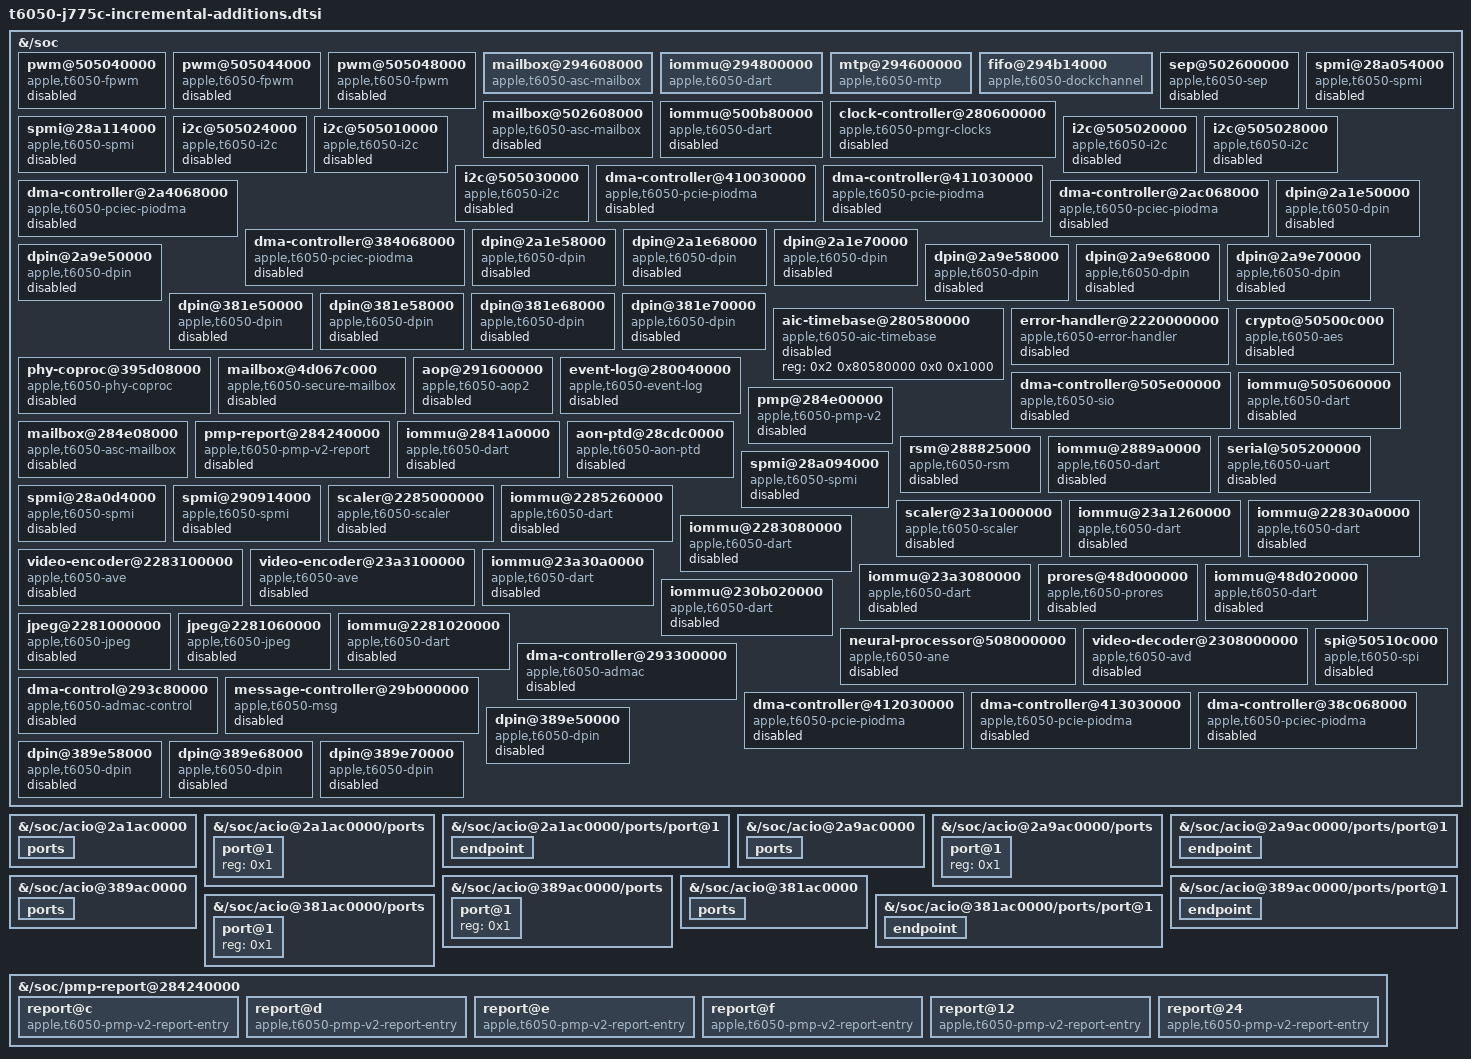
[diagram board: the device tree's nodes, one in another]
// SPDX-License-Identifier: GPL-2.0+ OR MIT
/* Property migration from Satya Benson's 86b1f365 J775c stack.
 * Retained board sources remain the baseline; this group is independently booted.
 * Copyright The Asahi Linux Contributors
 */
&{/soc} {
	pwm@505040000 {
		compatible = "apple,t6050-fpwm", "apple,s5l-fpwm";
		reg = <0x5 0x5040000 0x0 0x4000>;
		clocks = <&{/clock-ref}>;
		power-domains = <&{/soc/power-management@280900000/power-controller@2a8}>;
		#pwm-cells = <0x2>;
		status = "disabled";
	};
};

&{/soc} {
	pwm@505044000 {
		compatible = "apple,t6050-fpwm", "apple,s5l-fpwm";
		reg = <0x5 0x5044000 0x0 0x4000>;
		clocks = <&{/clock-ref}>;
		power-domains = <&{/soc/power-management@280900000/power-controller@2b0}>;
		#pwm-cells = <0x2>;
		status = "disabled";
	};
};

&{/soc} {
	pwm@505048000 {
		compatible = "apple,t6050-fpwm", "apple,s5l-fpwm";
		reg = <0x5 0x5048000 0x0 0x4000>;
		clocks = <&{/clock-ref}>;
		power-domains = <&{/soc/power-management@280900000/power-controller@2b8}>;
		#pwm-cells = <0x2>;
		status = "disabled";
	};
};

&{/soc/acio@2a1ac0000} {
	ports {
		#address-cells = <0x1>;
		#size-cells = <0x0>;
	};
};

&{/soc/acio@2a1ac0000/ports} {
	port@1 {
		reg = <0x1>;
	};
};

&{/soc/acio@2a1ac0000/ports/port@1} {
	endpoint {
		remote-endpoint = <&{/soc/spmi@28a188000/usb-pd@c/connector/ports/port@3/endpoint}>;
	};
};

&{/soc/acio@2a9ac0000} {
	ports {
		#address-cells = <0x1>;
		#size-cells = <0x0>;
	};
};

&{/soc/acio@2a9ac0000/ports} {
	port@1 {
		reg = <0x1>;
	};
};

&{/soc/acio@2a9ac0000/ports/port@1} {
	endpoint {
		remote-endpoint = <&{/soc/spmi@28a188000/usb-pd@a/connector/ports/port@3/endpoint}>;
	};
};

&{/soc/acio@389ac0000} {
	ports {
		#address-cells = <0x1>;
		#size-cells = <0x0>;
	};
};

&{/soc/acio@389ac0000/ports} {
	port@1 {
		reg = <0x1>;
	};
};

&{/soc/acio@389ac0000/ports/port@1} {
	endpoint {
		remote-endpoint = <&{/soc/spmi@28a188000/usb-pd@6/connector/ports/port@3/endpoint}>;
	};
};

&{/soc} {
	mailbox@294608000 {
		compatible = "apple,t6050-asc-mailbox", "apple,asc-mailbox-v4";
		reg = <0x2 0x94608000 0x0 0x4000>;
		interrupts = <0x0 0x0 0x2a4 0x4 0x0 0x0 0x2a5 0x4 0x0 0x0 0x2a6 0x4 0x0 0x0 0x2a7 0x4>;
		interrupt-names = "send-empty", "send-not-empty", "recv-empty", "recv-not-empty";
		#mbox-cells = <0x0>;
	};
};

&{/soc} {
	iommu@294800000 {
		compatible = "apple,t6050-dart", "apple,t8110-dart";
		reg = <0x2 0x94800000 0x0 0xc000>;
		interrupts = <0x0 0x0 0x293 0x4>;
		#iommu-cells = <0x1>;
		apple,dma-range = <0x100 0x4000 0x0 0xffff0000>;
	};
};

&{/soc} {
	mtp@294600000 {
		compatible = "apple,t6050-mtp", "apple,t6050-rtk-helper-asc4", "apple,mtp", "apple,rtk-helper-asc4";
		reg = <0x2 0x94600000 0x0 0x4000 0x2 0x94c00000 0x0 0xc4000>;
		reg-names = "asc", "sram";
		mboxes = <&{/soc/mailbox@294608000}>;
		iommus = <&{/soc/iommu@294800000} 0x0>;
		#helper-cells = <0x0>;
	};
};

&{/soc} {
	fifo@294b14000 {
		compatible = "apple,t6050-dockchannel", "apple,dockchannel";
		reg = <0x2 0x94b14000 0x0 0x1000>;
		reg-names = "irq";
		interrupts = <0x0 0x0 0x294 0x4>;
		ranges = <0x0 0x2 0x94b28000 0x10000>;
		nonposted-mmio;
		#address-cells = <0x1>;
		#size-cells = <0x1>;
		interrupt-controller;
		#interrupt-cells = <0x2>;
	};
};

&{/soc/acio@381ac0000} {
	ports {
		#address-cells = <0x1>;
		#size-cells = <0x0>;
	};
};

&{/soc/acio@381ac0000/ports} {
	port@1 {
		reg = <0x1>;
	};
};

&{/soc/acio@381ac0000/ports/port@1} {
	endpoint {
		remote-endpoint = <&{/soc/spmi@28a188000/usb-pd@8/connector/ports/port@3/endpoint}>;
	};
};

&{/soc} {
	sep@502600000 {
		compatible = "apple,t6050-sep", "apple,sep";
		reg = <0x5 0x2600000 0x0 0x88000 0x5 0x2050000 0x0 0x4000>;
		mboxes = <&{/soc/mailbox@502608000}>;
		mbox-names = "mbox";
		iommus = <&{/soc/iommu@500b80000} 0x0>;
		power-domains = <&{/soc/power-management@280900000/power-controller@298}>;
		clocks = <&{/soc/clock-controller@280600000} 0x1bf>;
		status = "disabled";
	};
};

&{/soc} {
	mailbox@502608000 {
		compatible = "apple,t6050-asc-mailbox", "apple,asc-mailbox-v4";
		reg = <0x5 0x2608000 0x0 0x4000>;
		interrupts = <0x0 0x0 0x215 0x4 0x0 0x0 0x216 0x4 0x0 0x0 0x217 0x4 0x0 0x0 0x218 0x4>;
		interrupt-names = "send-empty", "send-not-empty", "recv-empty", "recv-not-empty";
		#mbox-cells = <0x0>;
		status = "disabled";
	};
};

&{/soc} {
	iommu@500b80000 {
		compatible = "apple,t6050-dart", "apple,t8110-dart";
		reg = <0x5 0xb80000 0x0 0x20000>;
		interrupts = <0x0 0x0 0x21f 0x4>;
		#iommu-cells = <0x1>;
		apple,dma-range = <0x100 0x4000 0x0 0xffff0000>;
		apple,dma-offset = <0x0 0x0>;
		status = "disabled";
	};
};

&{/soc} {
	clock-controller@280600000 {
		compatible = "apple,t6050-pmgr-clocks", "apple,pmgr-clocks";
		reg = <0x2 0x80600000 0x0 0x1fc000 0x2 0x80900000 0x0 0x58000 0x2 0x80000000 0x0 0x80000 0x2 0x80210000 0x0 0x8000 0x2 0x80200000 0x0 0x4000 0x2 0x806f0000 0x0 0x4000 0x2 0x84000000 0x0 0x8000 0x2 0x84240000 0x0 0x40000 0x2 0x86000000 0x0 0x1000000 0x2 0x88300000 0x0 0x84000 0x2 0x88200000 0x0 0x80000 0x2 0x88f00000 0x0 0x18000 0x2 0x88000000 0x0 0x24000 0x2 0x88e00000 0x0 0xa8000 0x2 0x88360000 0x0 0x4000 0x5 0x9878000 0x0 0x4000 0x2 0x10e20000 0x0 0x12e8 0x2 0x10e40000 0x0 0xc020 0x2 0x10e50000 0x0 0x9048 0x2 0x10e70000 0x0 0xffe8 0x2 0x10050000 0x0 0x9018 0x2 0x10150000 0x0 0x9018 0x2 0x10250000 0x0 0x9018 0x2 0x10350000 0x0 0x9018 0x2 0x10450000 0x0 0x9018 0x2 0x10550000 0x0 0x9018 0x2 0x11e20000 0x0 0x12e8 0x2 0x11e40000 0x0 0xc020 0x2 0x11e50000 0x0 0x9048 0x2 0x11e70000 0x0 0xffe8 0x2 0x11050000 0x0 0x9018 0x2 0x11150000 0x0 0x9018 0x2 0x11250000 0x0 0x9018 0x2 0x11350000 0x0 0x9018 0x2 0x11450000 0x0 0x9018 0x2 0x11550000 0x0 0x9018 0x2 0x12e20000 0x0 0x12e8 0x2 0x12e40000 0x0 0xc020 0x2 0x12e50000 0x0 0x9048 0x2 0x12e70000 0x0 0xffe8 0x2 0x12050000 0x0 0x9018 0x2 0x12150000 0x0 0x9018 0x2 0x12250000 0x0 0x9018 0x2 0x12350000 0x0 0x9018 0x2 0x12450000 0x0 0x9018 0x2 0x12550000 0x0 0x9018 0x23 0x80600000 0x0 0x1e8000 0x23 0x80000000 0x0 0x80000 0x23 0x84000000 0x0 0x8000 0x23 0x88300000 0x0 0x84000 0x23 0x88200000 0x0 0x80000 0x23 0xe80000 0x0 0x30000 0x23 0xec0000 0x0 0x8000 0x23 0xed0000 0x0 0x8000 0x23 0xee0000 0x0 0x8000 0x23 0xef0000 0x0 0x8000 0x23 0xf00000 0x0 0x8000 0x23 0xe30000 0x0 0x8000 0x23 0xe70000 0x0 0x8000 0x23 0x88000000 0x0 0x8000>;
		#clock-cells = <0x1>;
		apple,pmgr = <&{/soc/power-management@280600000}>;
		status = "disabled";
	};
};

&{/soc} {
	spmi@28a054000 {
		compatible = "apple,t6050-spmi", "apple,t8142-spmi";
		reg = <0x2 0x8a054000 0x0 0x4000 0x2 0x8a044000 0x0 0x4000 0x2 0x8a040000 0x0 0x4000>;
		interrupts = <0x0 0x0 0x2db 0x4>;
		#address-cells = <0x2>;
		#size-cells = <0x0>;
		status = "disabled";
	};
};

&{/soc} {
	spmi@28a114000 {
		compatible = "apple,t6050-spmi", "apple,t8142-spmi";
		reg = <0x2 0x8a114000 0x0 0x4000 0x2 0x8a104000 0x0 0x4000 0x2 0x8a100000 0x0 0x4000>;
		interrupts = <0x0 0x0 0x2ea 0x4>;
		#address-cells = <0x2>;
		#size-cells = <0x0>;
		status = "disabled";
	};
};

&{/soc} {
	i2c@505024000 {
		compatible = "apple,t6050-i2c", "apple,t8103-i2c";
		reg = <0x5 0x5024000 0x0 0x4000>;
		interrupts = <0x0 0x0 0x564 0x4>;
		power-domains = <&{/soc/power-management@280900000/power-controller@2e8}>;
		clocks = <&{/soc/clock-controller@280600000} 0x4>;
		#address-cells = <0x1>;
		#size-cells = <0x0>;
		status = "disabled";
	};
};

&{/soc} {
	i2c@505010000 {
		compatible = "apple,t6050-i2c", "apple,t8103-i2c";
		reg = <0x5 0x5010000 0x0 0x4000>;
		interrupts = <0x0 0x0 0x55f 0x4>;
		power-domains = <&{/soc/power-management@280900000/power-controller@2c0}>;
		clocks = <&{/soc/clock-controller@280600000} 0x4>;
		#address-cells = <0x1>;
		#size-cells = <0x0>;
		status = "disabled";
	};
};

&{/soc} {
	i2c@505020000 {
		compatible = "apple,t6050-i2c", "apple,t8103-i2c";
		reg = <0x5 0x5020000 0x0 0x4000>;
		interrupts = <0x0 0x0 0x563 0x4>;
		power-domains = <&{/soc/power-management@280900000/power-controller@2e0}>;
		clocks = <&{/soc/clock-controller@280600000} 0x4>;
		#address-cells = <0x1>;
		#size-cells = <0x0>;
		status = "disabled";
	};
};

&{/soc} {
	i2c@505028000 {
		compatible = "apple,t6050-i2c", "apple,t8103-i2c";
		reg = <0x5 0x5028000 0x0 0x4000>;
		interrupts = <0x0 0x0 0x565 0x4>;
		power-domains = <&{/soc/power-management@280900000/power-controller@2f0}>;
		clocks = <&{/soc/clock-controller@280600000} 0x4>;
		#address-cells = <0x1>;
		#size-cells = <0x0>;
		status = "disabled";
	};
};

&{/soc} {
	i2c@505030000 {
		compatible = "apple,t6050-i2c", "apple,t8103-i2c";
		reg = <0x5 0x5030000 0x0 0x4000>;
		interrupts = <0x0 0x0 0x567 0x4>;
		power-domains = <&{/soc/power-management@280900000/power-controller@300}>;
		clocks = <&{/soc/clock-controller@280600000} 0x4>;
		#address-cells = <0x1>;
		#size-cells = <0x0>;
		status = "disabled";
	};
};

&{/soc} {
	dma-controller@410030000 {
		compatible = "apple,t6050-pcie-piodma", "apple,pcie-piodma";
		reg = <0x4 0x10030000 0x0 0x4000 0x4 0x10034000 0x0 0x4000 0x4 0x10038000 0x0 0x4000>;
		interrupts = <0x0 0x0 0x5f5 0x4>;
		iommus = <&{/soc/iommu@410000000} 0x11>;
		status = "disabled";
	};
};

&{/soc} {
	dma-controller@411030000 {
		compatible = "apple,t6050-pcie-piodma", "apple,pcie-piodma";
		reg = <0x4 0x11030000 0x0 0x4000 0x4 0x11034000 0x0 0x4000 0x4 0x11038000 0x0 0x4000>;
		interrupts = <0x0 0x0 0x5fd 0x4>;
		iommus = <&{/soc/iommu@411000000} 0x11>;
		status = "disabled";
	};
};

&{/soc} {
	dma-controller@2a4068000 {
		compatible = "apple,t6050-pciec-piodma", "apple,pciec-piodma";
		reg = <0x2 0xa4068000 0x0 0x4000 0x2 0xa406c000 0x0 0x4000 0x2 0xa4070000 0x0 0x4000 0x2 0xa403c000 0x0 0x4000>;
		interrupts = <0x0 0x0 0x57f 0x4>;
		iommus = <&{/soc/iommu@2a4000000} 0xfe>;
		status = "disabled";
	};
};

&{/soc} {
	dma-controller@2ac068000 {
		compatible = "apple,t6050-pciec-piodma", "apple,pciec-piodma";
		reg = <0x2 0xac068000 0x0 0x4000 0x2 0xac06c000 0x0 0x4000 0x2 0xac070000 0x0 0x4000 0x2 0xac03c000 0x0 0x4000>;
		interrupts = <0x0 0x0 0x59f 0x4>;
		iommus = <&{/soc/iommu@2ac000000} 0xfe>;
		status = "disabled";
	};
};

&{/soc} {
	dma-controller@384068000 {
		compatible = "apple,t6050-pciec-piodma", "apple,pciec-piodma";
		reg = <0x3 0x84068000 0x0 0x4000 0x3 0x8406c000 0x0 0x4000 0x3 0x84070000 0x0 0x4000 0x3 0x8403c000 0x0 0x4000>;
		interrupts = <0x0 0x0 0x5bf 0x4>;
		iommus = <&{/soc/iommu@384000000} 0xfe>;
		status = "disabled";
	};
};

&{/soc} {
	dpin@2a1e50000 {
		compatible = "apple,t6050-dpin", "apple,dpin";
		reg = <0x2 0xa1e50000 0x0 0x4000>;
		interrupts = <0x0 0x0 0x643 0x4>;
		status = "disabled";
	};
};

&{/soc} {
	dpin@2a1e58000 {
		compatible = "apple,t6050-dpin", "apple,dpin";
		reg = <0x2 0xa1e58000 0x0 0x4000>;
		interrupts = <0x0 0x0 0x644 0x4>;
		status = "disabled";
	};
};

&{/soc} {
	dpin@2a1e68000 {
		compatible = "apple,t6050-dpin", "apple,dpin";
		reg = <0x2 0xa1e68000 0x0 0x4000>;
		interrupts = <0x0 0x0 0x649 0x4>;
		status = "disabled";
	};
};

&{/soc} {
	dpin@2a1e70000 {
		compatible = "apple,t6050-dpin", "apple,dpin";
		reg = <0x2 0xa1e70000 0x0 0x4000>;
		interrupts = <0x0 0x0 0x64a 0x4>;
		status = "disabled";
	};
};

&{/soc} {
	dpin@2a9e50000 {
		compatible = "apple,t6050-dpin", "apple,dpin";
		reg = <0x2 0xa9e50000 0x0 0x4000>;
		interrupts = <0x0 0x0 0x663 0x4>;
		status = "disabled";
	};
};

&{/soc} {
	dpin@2a9e58000 {
		compatible = "apple,t6050-dpin", "apple,dpin";
		reg = <0x2 0xa9e58000 0x0 0x4000>;
		interrupts = <0x0 0x0 0x664 0x4>;
		status = "disabled";
	};
};

&{/soc} {
	dpin@2a9e68000 {
		compatible = "apple,t6050-dpin", "apple,dpin";
		reg = <0x2 0xa9e68000 0x0 0x4000>;
		interrupts = <0x0 0x0 0x669 0x4>;
		status = "disabled";
	};
};

&{/soc} {
	dpin@2a9e70000 {
		compatible = "apple,t6050-dpin", "apple,dpin";
		reg = <0x2 0xa9e70000 0x0 0x4000>;
		interrupts = <0x0 0x0 0x66a 0x4>;
		status = "disabled";
	};
};

&{/soc} {
	dpin@381e50000 {
		compatible = "apple,t6050-dpin", "apple,dpin";
		reg = <0x3 0x81e50000 0x0 0x4000>;
		interrupts = <0x0 0x0 0x683 0x4>;
		status = "disabled";
	};
};

&{/soc} {
	dpin@381e58000 {
		compatible = "apple,t6050-dpin", "apple,dpin";
		reg = <0x3 0x81e58000 0x0 0x4000>;
		interrupts = <0x0 0x0 0x684 0x4>;
		status = "disabled";
	};
};

&{/soc} {
	dpin@381e68000 {
		compatible = "apple,t6050-dpin", "apple,dpin";
		reg = <0x3 0x81e68000 0x0 0x4000>;
		interrupts = <0x0 0x0 0x689 0x4>;
		status = "disabled";
	};
};

&{/soc} {
	dpin@381e70000 {
		compatible = "apple,t6050-dpin", "apple,dpin";
		reg = <0x3 0x81e70000 0x0 0x4000>;
		interrupts = <0x0 0x0 0x68a 0x4>;
		status = "disabled";
	};
};

&{/soc} {
	aic-timebase@280580000 {
		compatible = "apple,t6050-aic-timebase", "apple,aic-timebase";
		reg = <0x2 0x80580000 0x0 0x1000>;
		status = "disabled";
	};
};

&{/soc} {
	error-handler@2220000000 {
		compatible = "apple,t6050-error-handler", "apple,soc-error-handler";
		reg = <0x22 0x20000000 0x0 0x240000 0x22 0x20270000 0x0 0x1d0000 0x22 0x20600000 0x0 0x40000 0x22 0x20670000 0x0 0x1d0000 0x22 0x22000000 0x0 0x240000 0x22 0x22270000 0x0 0x1d0000 0x22 0x22600000 0x0 0x40000 0x22 0x22670000 0x0 0x1d0000 0x2 0x80000000 0x0 0x80000 0x2 0x80650000 0x0 0x4000 0x2 0x806e0000 0x0 0xc000 0x2 0x80210000 0x0 0x4000 0x2 0x88374000 0x0 0x4000 0x2 0x86000000 0x0 0x1000000 0x2 0x84250000 0x0 0x4000 0x22 0x63000000 0x0 0x38000 0x22 0x64000000 0x0 0x38000 0x22 0x65000000 0x0 0x38000 0x2 0x63000000 0x0 0x44000 0x2 0x64000000 0x0 0x30000 0x2 0x65000000 0x0 0x3c000 0x2 0x66000000 0x0 0x34000 0x2 0x67000000 0x0 0x38000 0x2 0x68000000 0x0 0x38000 0x2 0x69000000 0x0 0x30000 0x22 0x5a100000 0x0 0x24000 0x22 0x5b100000 0x0 0x24000 0x22 0x5c100000 0x0 0x24000 0x22 0x5d100000 0x0 0x24000 0x2 0x4f000000 0x0 0x30000 0x2 0x50000000 0x0 0x30000 0x2 0x51000000 0x0 0x30000 0x2 0x52000000 0x0 0x24000 0x2 0x62000000 0x0 0x1c000 0x22 0x62000000 0x0 0x1c000 0x22 0x5a000000 0x0 0x2c000 0x22 0x5b000000 0x0 0x2c000 0x22 0x5c000000 0x0 0x2c000 0x22 0x5d000000 0x0 0x2c000 0x22 0x5a200000 0x0 0x1c000 0x22 0x5a300000 0x0 0x1c000 0x22 0x5b200000 0x0 0x1c000 0x22 0x5b300000 0x0 0x1c000 0x2 0x6a000000 0x0 0x1c000 0x2 0x6b000000 0x0 0x1c000 0x2 0x6c000000 0x0 0x1c000 0x2 0x6d000000 0x0 0x1c000 0x22 0x66000000 0x0 0x1c000 0x22 0x67000000 0x0 0x1c000 0x22 0x68000000 0x0 0x1c000 0x22 0x69000000 0x0 0x1c000 0x22 0x75000000 0x0 0x10000 0x22 0x75010000 0x0 0x10000 0x22 0x75020000 0x0 0x10000 0x22 0x75030000 0x0 0x10000 0x22 0x75400000 0x0 0x10000 0x22 0x75410000 0x0 0x10000 0x22 0x75420000 0x0 0x10000 0x22 0x75430000 0x0 0x10000 0x22 0x75800000 0x0 0x10000 0x22 0x75810000 0x0 0x10000 0x22 0x75820000 0x0 0x10000 0x22 0x75830000 0x0 0x10000 0x22 0x75c00000 0x0 0x10000 0x22 0x75c10000 0x0 0x10000 0x22 0x75c20000 0x0 0x10000 0x22 0x75c30000 0x0 0x10000 0x22 0x76000000 0x0 0x10000 0x22 0x76010000 0x0 0x10000 0x22 0x76020000 0x0 0x10000 0x22 0x76030000 0x0 0x10000 0x22 0x76400000 0x0 0x10000 0x22 0x76410000 0x0 0x10000 0x22 0x76420000 0x0 0x10000 0x22 0x76430000 0x0 0x10000 0x22 0x76800000 0x0 0x10000 0x22 0x76810000 0x0 0x10000 0x22 0x76820000 0x0 0x10000 0x22 0x76830000 0x0 0x10000 0x22 0x76c00000 0x0 0x10000 0x22 0x76c10000 0x0 0x10000 0x22 0x76c20000 0x0 0x10000 0x22 0x76c30000 0x0 0x10000 0x22 0x77000000 0x0 0x10000 0x22 0x77010000 0x0 0x10000 0x22 0x77020000 0x0 0x10000 0x22 0x77030000 0x0 0x10000 0x22 0x77040000 0x0 0x10000 0x22 0x77050000 0x0 0x10000 0x22 0x77400000 0x0 0x10000 0x22 0x77410000 0x0 0x10000 0x22 0x77420000 0x0 0x10000 0x22 0x77430000 0x0 0x10000 0x22 0x77440000 0x0 0x10000 0x22 0x77450000 0x0 0x10000 0x22 0x77800000 0x0 0x10000 0x22 0x77810000 0x0 0x10000 0x22 0x77820000 0x0 0x10000 0x22 0x77830000 0x0 0x10000 0x22 0x77840000 0x0 0x10000 0x22 0x77850000 0x0 0x10000 0x22 0x77c00000 0x0 0x10000 0x22 0x77c10000 0x0 0x10000 0x22 0x77c20000 0x0 0x10000 0x22 0x77c30000 0x0 0x10000 0x22 0x77c40000 0x0 0x10000 0x22 0x77c50000 0x0 0x10000 0x2 0x73000000 0x0 0x10000 0x2 0x73010000 0x0 0x10000 0x2 0x73020000 0x0 0x10000 0x2 0x73030000 0x0 0x10000 0x2 0x73040000 0x0 0x10000 0x2 0x73050000 0x0 0x10000 0x2 0x73060000 0x0 0x10000 0x2 0x73400000 0x0 0x10000 0x2 0x73410000 0x0 0x10000 0x2 0x73420000 0x0 0x10000 0x2 0x73430000 0x0 0x10000 0x2 0x73440000 0x0 0x10000 0x2 0x73450000 0x0 0x10000 0x2 0x73460000 0x0 0x10000 0x2 0x73800000 0x0 0x10000 0x2 0x73810000 0x0 0x10000 0x2 0x73820000 0x0 0x10000 0x2 0x73830000 0x0 0x10000 0x2 0x73840000 0x0 0x10000 0x2 0x73850000 0x0 0x10000 0x2 0x73860000 0x0 0x10000 0x2 0x73c00000 0x0 0x10000 0x2 0x73c10000 0x0 0x10000 0x2 0x73c20000 0x0 0x10000 0x2 0x73c30000 0x0 0x10000 0x2 0x73c40000 0x0 0x10000 0x2 0x73c50000 0x0 0x10000 0x2 0x73c60000 0x0 0x10000 0x22 0x75100000 0x0 0x10000 0x22 0x75110000 0x0 0x10000 0x22 0x75120000 0x0 0x10000 0x22 0x75130000 0x0 0x10000 0x22 0x75500000 0x0 0x10000 0x22 0x75510000 0x0 0x10000 0x22 0x75520000 0x0 0x10000 0x22 0x75530000 0x0 0x10000 0x22 0x75900000 0x0 0x10000 0x22 0x75910000 0x0 0x10000 0x22 0x75920000 0x0 0x10000 0x22 0x75930000 0x0 0x10000 0x22 0x75d00000 0x0 0x10000 0x22 0x75d10000 0x0 0x10000 0x22 0x75d20000 0x0 0x10000 0x22 0x75d30000 0x0 0x10000 0x22 0x76100000 0x0 0x10000 0x22 0x76110000 0x0 0x10000 0x22 0x76120000 0x0 0x10000 0x22 0x76130000 0x0 0x10000 0x22 0x76500000 0x0 0x10000 0x22 0x76510000 0x0 0x10000 0x22 0x76520000 0x0 0x10000 0x22 0x76530000 0x0 0x10000 0x22 0x76900000 0x0 0x10000 0x22 0x76910000 0x0 0x10000 0x22 0x76920000 0x0 0x10000 0x22 0x76930000 0x0 0x10000 0x22 0x76d00000 0x0 0x10000 0x22 0x76d10000 0x0 0x10000 0x22 0x76d20000 0x0 0x10000 0x22 0x76d30000 0x0 0x10000 0x2 0x58000000 0x0 0x10000 0x2 0x58010000 0x0 0x10000 0x2 0x58020000 0x0 0x10000 0x2 0x58030000 0x0 0x10000 0x2 0x58040000 0x0 0x10000 0x2 0x58400000 0x0 0x10000 0x2 0x58410000 0x0 0x10000 0x2 0x58420000 0x0 0x10000 0x2 0x58430000 0x0 0x10000 0x2 0x58440000 0x0 0x10000 0x2 0x58800000 0x0 0x10000 0x2 0x58810000 0x0 0x10000 0x2 0x58820000 0x0 0x10000 0x2 0x58830000 0x0 0x10000 0x2 0x58840000 0x0 0x10000 0x2 0x58850000 0x0 0x10000 0x5 0xd00000 0x0 0x40000 0x2 0x80078000 0x0 0x4000 0x2 0x806e4000 0x0 0x4000 0x2 0x806e8000 0x0 0x4000 0x2 0x74004000 0x0 0x4000 0x22 0x7b004000 0x0 0x4000 0x2 0x88000400 0x0 0x400 0x23 0x88000400 0x0 0x400 0x2 0x8c801000 0x0 0x400 0x2 0x84398000 0x0 0x4000 0x2 0x8620c020 0x0 0x18 0x2 0x8620c008 0x0 0x18 0x5 0x8000200 0x0 0x24 0x5 0x84000200 0x0 0x24 0x4 0x1b000200 0x0 0x24 0x2 0xa0000200 0x0 0x24 0x2 0xa8000200 0x0 0x24 0x3 0x80000200 0x0 0x24 0x3 0x88000200 0x0 0x24 0x3 0x94000200 0x0 0x24 0x23 0x8000200 0x0 0x24 0x23 0x1000200 0x0 0x24 0x5 0x80000200 0x0 0x24 0x22 0x80000200 0x0 0x24 0x4 0x16000200 0x0 0x24 0x4 0x86000200 0x0 0x40 0x23 0xa000200 0x0 0x24 0x2 0x97000200 0x0 0x24 0x23 0x8c000200 0x0 0x24 0x4 0x8c000200 0x0 0x24 0x5 0x4000200 0x0 0x24>;
		interrupts = <0x0 0x0 0xa95 0x4 0x0 0x0 0xa96 0x4 0x0 0x0 0xa97 0x4 0x0 0x0 0xa98 0x4 0x0 0x0 0xa99 0x4 0x0 0x0 0xa9a 0x4 0x0 0x0 0xa9b 0x4 0x0 0x0 0xa9c 0x4 0x0 0x0 0x189 0x4 0x0 0x0 0xc3 0x4 0x0 0x0 0xc4 0x4 0x0 0x0 0xc5 0x4 0x0 0x0 0xc6 0x4 0x0 0x0 0xc7 0x4 0x0 0x0 0xc8 0x4 0x0 0x0 0xc9 0x4 0x0 0x0 0xca 0x4 0x0 0x0 0xcb 0x4 0x0 0x0 0xcc 0x4 0x0 0x0 0xa0c 0x4 0x0 0x0 0xa0d 0x4 0x0 0x0 0xa0e 0x4 0x0 0x0 0xa0f 0x4 0x0 0x0 0x99 0x4 0x0 0x0 0x9a 0x4 0x0 0x0 0x9b 0x4 0x0 0x0 0x9c 0x4 0x0 0x0 0x9d 0x4 0x0 0x0 0x9e 0x4 0x0 0x0 0xa14 0x4 0x0 0x0 0xa15 0x4 0x0 0x0 0xa16 0x4 0x0 0x0 0xa17 0x4 0x0 0x0 0xa1c 0x4 0x0 0x0 0xa1d 0x4 0x0 0x0 0xa1e 0x4 0x0 0x0 0xa1f 0x4 0x0 0x0 0xbd 0x4 0x0 0x0 0xbe 0x4 0x0 0x0 0xbf 0x4 0x0 0x0 0xc0 0x4 0x0 0x0 0xa2c 0x4 0x0 0x0 0xa2d 0x4 0x0 0x0 0xa2e 0x4 0x0 0x0 0xa2f 0x4 0x0 0x0 0xa3e 0x4 0x0 0x0 0xa3f 0x4 0x0 0x0 0xa40 0x4 0x0 0x0 0xa41 0x4 0x0 0x0 0xa42 0x4 0x0 0x0 0xa43 0x4 0x0 0x0 0xa44 0x4 0x0 0x0 0xa45 0x4 0x0 0x0 0xa46 0x4 0x0 0x0 0xa47 0x4 0x0 0x0 0xa48 0x4 0x0 0x0 0xa49 0x4 0x0 0x0 0xa4a 0x4 0x0 0x0 0xa4b 0x4 0x0 0x0 0xa4c 0x4 0x0 0x0 0xa4d 0x4 0x0 0x0 0xa36 0x4 0x0 0x0 0xa37 0x4 0x0 0x0 0xa38 0x4 0x0 0x0 0xa39 0x4 0x0 0x0 0xa3a 0x4 0x0 0x0 0xa3b 0x4 0x0 0x0 0xa3c 0x4 0x0 0x0 0xa3d 0x4 0x0 0x0 0x9f 0x4 0x0 0x0 0xa0 0x4 0x0 0x0 0xa1 0x4 0x0 0x0 0x21e 0x4 0x0 0x0 0x21d 0x4 0x0 0x0 0x222 0x4 0x0 0x0 0x223 0x4 0x0 0x0 0x224 0x4 0x0 0x0 0x225 0x4 0x0 0x0 0x144 0x4 0x0 0x0 0xc1 0x4 0x0 0x0 0xc2 0x4 0x0 0x0 0x30d 0x4 0x0 0x0 0x30e 0x4 0x0 0x0 0x387 0x4 0x0 0x0 0x16f 0x4 0x0 0x0 0x1b9 0x4 0x0 0x0 0x3bc 0x4 0x0 0x0 0x3c2 0x4 0x0 0x0 0x548 0x4 0x0 0x0 0x573 0x4 0x0 0x0 0x593 0x4 0x0 0x0 0x5b3 0x4 0x0 0x0 0x5d3 0x4 0x0 0x0 0x928 0x4 0x0 0x0 0x97c 0x4 0x0 0x0 0x997 0x4 0x0 0x0 0x214 0x4 0x0 0x0 0x54d 0x4 0x0 0x0 0x613 0x4 0x0 0x0 0x620 0x4 0x0 0x0 0x6df 0x4 0x0 0x0 0x316 0x4 0x0 0x0 0x317 0x4 0x0 0x0 0x6af 0x4 0x0 0x0 0x56d 0x4>;
		status = "disabled";
	};
};

&{/soc} {
	crypto@50500c000 {
		compatible = "apple,t6050-aes", "apple,aes";
		reg = <0x5 0x500c000 0x0 0x4000 0x2 0x88340000 0x0 0x8000 0x2 0x88090000 0x0 0x4000>;
		interrupts = <0x0 0x0 0x55e 0x4>;
		iommus = <&{/soc/iommu@505060000} 0x1>;
		power-domains = <&{/soc/power-management@280900000/power-controller@318}>;
		status = "disabled";
	};
};

&{/soc} {
	phy-coproc@395d08000 {
		compatible = "apple,t6050-phy-coproc", "apple,phy-coproc";
		reg = <0x3 0x95d08000 0x0 0x4000 0x3 0x95d00000 0x0 0x4000>;
		interrupts = <0x0 0x0 0x92b 0x4 0x0 0x0 0x92a 0x4 0x0 0x0 0x92d 0x4 0x0 0x0 0x92c 0x4>;
		status = "disabled";
	};
};

&{/soc} {
	mailbox@4d067c000 {
		compatible = "apple,t6050-secure-mailbox", "apple,secure-mailbox";
		reg = <0x4 0xd067c000 0x0 0x4000>;
		interrupts = <0x0 0x0 0x249 0x4 0x0 0x0 0x246 0x4>;
		iommus = <&{/soc/iommu@290fc0000} 0x1>;
		status = "disabled";
	};
};

&{/soc} {
	aop@291600000 {
		compatible = "apple,t6050-aop2", "apple,aop2";
		reg = <0x2 0x91600000 0x0 0x88000 0x2 0x91650000 0x0 0x4000 0x2 0x9162c000 0x0 0x3c008>;
		interrupts = <0x0 0x0 0x24b 0x4 0x0 0x0 0x24a 0x4 0x0 0x0 0x24d 0x4 0x0 0x0 0x24c 0x4>;
		iommus = <&{/soc/iommu@290fc0000} 0x10>;
		status = "disabled";
	};
};

&{/soc} {
	event-log@280040000 {
		compatible = "apple,t6050-event-log", "apple,soc-event-log";
		reg = <0x2 0x80040000 0x0 0x4000 0x2 0x8004e000 0x0 0x4000 0x23 0x8004c800 0x0 0x4000 0x23 0x80040000 0x0 0x4000 0x2 0x80200000 0x0 0x4000 0x2 0x80000000 0x0 0x14000 0x2 0x8003c000 0x0 0x4000 0x2 0x80020000 0x0 0x10000 0x2 0x806e0000 0x0 0x4000 0x2 0x806d0000 0x0 0x4000 0x2 0x80668000 0x0 0x4000 0x2 0x80680000 0x0 0x1c000 0x2 0x807d0000 0x0 0x4000 0x2 0x806f0000 0x0 0x4000 0x2 0x80928000 0x0 0x4000 0x2 0x80938000 0x0 0x8000 0x2 0x86700000 0x0 0x114000 0x2 0x84380000 0x0 0x20000 0x2 0x85040000 0x0 0x1c000 0x2 0x84360000 0x0 0x4000 0x2 0x84370000 0x0 0x4000 0x23 0x85040000 0x0 0x1c000 0x23 0x84360000 0x0 0x4000 0x23 0x84370000 0x0 0x4000 0x5 0x9878000 0x0 0x4000 0x5 0x9868000 0x0 0x8000 0x23 0x80300000 0x0 0x8000 0x23 0x80308000 0x0 0x8000 0x2 0x80300000 0x0 0x8000 0x23 0x80034000 0x0 0x4000 0x23 0x8003c000 0x0 0x4000 0x23 0x80020000 0x0 0x10000 0x23 0x80038000 0x0 0x4000 0x23 0x80640000 0x0 0x10000 0x23 0x806d0000 0x0 0x4000 0x23 0x80668000 0x0 0x4000 0x23 0x80680000 0x0 0x1c000 0x23 0x806f0000 0x0 0x4000 0x2 0x84000000 0x0 0x4000 0x2 0x84004600 0x0 0x4000 0x2 0x84004000 0x0 0x4000 0x2 0x84004780 0x0 0x4000 0x2 0x84007400 0x0 0x4000 0x2 0x84004e00 0x0 0x4000 0x2 0x84004800 0x0 0x4000 0x2 0x84004f80 0x0 0x4000 0x2 0x84007600 0x0 0x4000 0x2 0x84005600 0x0 0x4000 0x2 0x84005000 0x0 0x4000 0x2 0x84005780 0x0 0x4000 0x2 0x84007800 0x0 0x4000 0x2 0x84005e00 0x0 0x4000 0x2 0x84005800 0x0 0x4000 0x2 0x84005f80 0x0 0x4000 0x2 0x84007a00 0x0 0x4000 0x2 0x84003e00 0x0 0x4000 0x2 0x84003800 0x0 0x4000 0x2 0x84003f80 0x0 0x4000 0x2 0x84007200 0x0 0x4000 0x2 0x84006e00 0x0 0x4000 0x2 0x84006800 0x0 0x4000 0x2 0x84006f80 0x0 0x4000 0x2 0x84007e00 0x0 0x4000 0x2 0x84006600 0x0 0x4000 0x2 0x84006000 0x0 0x4000 0x2 0x84006780 0x0 0x4000 0x2 0x84007c00 0x0 0x4000 0x2 0x84002e00 0x0 0x4000 0x2 0x84002800 0x0 0x4000 0x2 0x84002f80 0x0 0x4000 0x2 0x84007000 0x0 0x4000 0x2 0x84003600 0x0 0x4000 0x2 0x84003000 0x0 0x4000 0x2 0x84003780 0x0 0x4000 0x2 0x84000400 0x0 0x4000 0x2 0x84000400 0x0 0x4000 0x2 0x84000400 0x0 0x4000 0x2 0x84000400 0x0 0x4000 0x2 0x84000400 0x0 0x4000 0x2 0x84000400 0x0 0x4000 0x2 0x84000400 0x0 0x4000 0x2 0x84000400 0x0 0x4000 0x23 0x84000000 0x0 0x4000 0x23 0x84004e00 0x0 0x4000 0x23 0x84004800 0x0 0x4000 0x23 0x84004f80 0x0 0x4000 0x23 0x84007000 0x0 0x4000 0x23 0x84002e00 0x0 0x4000 0x23 0x84002800 0x0 0x4000 0x23 0x84002f80 0x0 0x4000 0x23 0x84006800 0x0 0x4000 0x23 0x84003600 0x0 0x4000 0x23 0x84003000 0x0 0x4000 0x23 0x84003780 0x0 0x4000 0x23 0x84006a00 0x0 0x4000 0x23 0x84005600 0x0 0x4000 0x23 0x84005000 0x0 0x4000 0x23 0x84005780 0x0 0x4000 0x23 0x84007200 0x0 0x4000 0x23 0x84006600 0x0 0x4000 0x23 0x84006000 0x0 0x4000 0x23 0x84006780 0x0 0x4000 0x23 0x84007400 0x0 0x4000 0x23 0x84005e00 0x0 0x4000 0x23 0x84005800 0x0 0x4000 0x23 0x84005f80 0x0 0x4000 0x23 0x84003e00 0x0 0x4000 0x23 0x84003800 0x0 0x4000 0x23 0x84003f80 0x0 0x4000 0x23 0x84006c00 0x0 0x4000 0x23 0x84004600 0x0 0x4000 0x23 0x84004000 0x0 0x4000 0x23 0x84004780 0x0 0x4000 0x23 0x84006e00 0x0 0x4000 0x23 0x84000400 0x0 0x4000 0x23 0x84000400 0x0 0x4000 0x23 0x84000400 0x0 0x4000 0x23 0x84000400 0x0 0x4000 0x23 0x84000400 0x0 0x4000 0x23 0x84000400 0x0 0x4000 0x23 0x84000400 0x0 0x4000 0x23 0x84000400 0x0 0x4000 0x2 0x88f00000 0x0 0x18000 0x2 0x88200000 0x0 0x4000 0x2 0x88204000 0x0 0x4000 0x2 0x8827c000 0x0 0x4000 0x2 0x8832c000 0x0 0x4000 0x2 0x88330000 0x0 0x10000 0x2 0x88360000 0x0 0x4000 0x2 0x88340000 0x0 0x8000 0x2 0x8836c000 0x0 0x4000 0x2 0x88000000 0x0 0x24000 0x23 0x88200000 0x0 0x4000 0x23 0x88204000 0x0 0x4000 0x23 0x8827c000 0x0 0x4000 0x23 0x8832c000 0x0 0x4000 0x23 0x88330000 0x0 0x10000 0x23 0x88360000 0x0 0x4000 0x23 0x88340000 0x0 0x8000 0x23 0x8836c000 0x0 0x4000 0x23 0x88000000 0x0 0x8000>;
		interrupts = <0x0 0x0 0x1e 0x4 0x0 0x0 0x1f 0x4 0x0 0x0 0x22 0x4 0x0 0x0 0x23 0x4 0x0 0x0 0x24 0x4 0x0 0x0 0x37 0x4 0x0 0x0 0x38 0x4 0x0 0x0 0x13f 0x4 0x0 0x0 0x140 0x4 0x0 0x0 0x141 0x4 0x0 0x0 0x147 0x4 0x0 0x0 0x148 0x4 0x0 0x0 0x170 0x4 0x0 0x0 0x17e 0x4 0x0 0x0 0x1db 0x4 0x0 0x0 0x1e0 0x4 0x0 0x0 0x1e1 0x4 0x0 0x0 0x1e4 0x4 0x0 0x0 0x1e5 0x4 0x0 0x0 0x30f 0x4 0x0 0x0 0x310 0x4 0x0 0x0 0x3af 0x4 0x0 0x0 0x3b7 0x4>;
		status = "disabled";
	};
};

&{/soc} {
	dma-controller@505e00000 {
		compatible = "apple,t6050-sio", "apple,sio";
		reg = <0x5 0x5e00000 0x0 0x88000 0x5 0x5850000 0x0 0x4000>;
		interrupts = <0x0 0x0 0x570 0x4 0x0 0x0 0x56f 0x4 0x0 0x0 0x572 0x4 0x0 0x0 0x571 0x4>;
		iommus = <&{/soc/iommu@505060000} 0x0>;
		power-domains = <&{/soc/power-management@280900000/power-controller@2a0}>;
		clocks = <&{/soc/clock-controller@280600000} 0x167 &{/soc/clock-controller@280600000} 0x166>;
		#dma-cells = <0x1>;
		status = "disabled";
	};
};

&{/soc} {
	iommu@505060000 {
		compatible = "apple,t6050-dart", "apple,t8110-dart";
		reg = <0x5 0x5060000 0x0 0x20000>;
		interrupts = <0x0 0x0 0x56b 0x4>;
		power-domains = <&{/soc/power-management@280900000/power-controller@290}>;
		#iommu-cells = <0x1>;
		status = "disabled";
	};
};

&{/soc} {
	pmp@284e00000 {
		compatible = "apple,t6050-pmp-v2", "apple,t6000-pmp-v2";
		reg = <0x2 0x84500000 0x0 0x100000 0x2 0x84e00000 0x0 0x4000>;
		reg-names = "pmp", "asc";
		mboxes = <&{/soc/mailbox@284e08000}>;
		mbox-names = "mbox";
		iommus = <&{/soc/iommu@2841a0000} 0x0>;
		power-domains = <&{/soc/power-management@280600000/power-controller@128} &{/soc/power-management@280600000/power-controller@130}>;
		status = "disabled";
	};
};

&{/soc} {
	mailbox@284e08000 {
		compatible = "apple,t6050-asc-mailbox", "apple,asc-mailbox-v4";
		reg = <0x2 0x84e08000 0x0 0x4000>;
		interrupts = <0x0 0x0 0x18c 0x4 0x0 0x0 0x18d 0x4 0x0 0x0 0x18e 0x4 0x0 0x0 0x18f 0x4>;
		interrupt-names = "send-empty", "send-not-empty", "recv-empty", "recv-not-empty";
		#mbox-cells = <0x0>;
		power-domains = <&{/soc/power-management@280600000/power-controller@128}>;
		status = "disabled";
	};
};

&{/soc} {
	pmp-report@284240000 {
		compatible = "apple,t6050-pmp-v2-report";
		reg = <0x2 0x84240000 0x0 0x20000>;
		power-domains = <&{/soc/power-management@280600000/power-controller@130}>;
		#address-cells = <0x1>;
		#size-cells = <0x0>;
		status = "disabled";
	};
};

&{/soc/pmp-report@284240000} {
	report@c {
		compatible = "apple,t6050-pmp-v2-report-entry", "apple,t6000-pmp-v2-report-entry";
		reg = <0xc>;
		label = "pmp-macc0";
		#power-domain-cells = <0x0>;
		apple,always-on;
	};
};

&{/soc/pmp-report@284240000} {
	report@d {
		compatible = "apple,t6050-pmp-v2-report-entry", "apple,t6000-pmp-v2-report-entry";
		reg = <0xd>;
		label = "pmp-macc1";
		#power-domain-cells = <0x0>;
		apple,always-on;
	};
};

&{/soc/pmp-report@284240000} {
	report@e {
		compatible = "apple,t6050-pmp-v2-report-entry", "apple,t6000-pmp-v2-report-entry";
		reg = <0xe>;
		label = "pmp-pacc";
		#power-domain-cells = <0x0>;
		apple,always-on;
	};
};

&{/soc/pmp-report@284240000} {
	report@f {
		compatible = "apple,t6050-pmp-v2-report-entry", "apple,t6000-pmp-v2-report-entry";
		reg = <0xf>;
		label = "pmp-gfx";
		#power-domain-cells = <0x0>;
		power-domains = <&{/soc@2300000000/power-management@2300e80000/power-controller@110}>;
	};
};

&{/soc/pmp-report@284240000} {
	report@12 {
		compatible = "apple,t6050-pmp-v2-report-entry", "apple,t6000-pmp-v2-report-entry";
		reg = <0x12>;
		label = "pmp-dispint";
		#power-domain-cells = <0x0>;
		apple,always-on;
	};
};

&{/soc/pmp-report@284240000} {
	report@24 {
		compatible = "apple,t6050-pmp-v2-report-entry", "apple,t6000-pmp-v2-report-entry";
		reg = <0x24>;
		label = "pmp-ans";
		#power-domain-cells = <0x0>;
		apple,always-on;
	};
};

&{/soc} {
	iommu@2841a0000 {
		compatible = "apple,t6050-dart", "apple,t8110-dart";
		reg = <0x2 0x841a0000 0x0 0xc000 0x2 0x841b0000 0x0 0x4000>;
		reg-names = "dart", "dapf";
		interrupts = <0x0 0x0 0x173 0x4>;
		#iommu-cells = <0x1>;
		apple,dma-range = <0x100 0x0 0x10 0x0>;
		power-domains = <&{/soc/power-management@280600000/power-controller@128}>;
		status = "disabled";
	};
};

&{/soc} {
	aon-ptd@28cdc0000 {
		compatible = "apple,t6050-aon-ptd", "apple,aon-ptd";
		reg = <0x2 0x8cdc0000 0x0 0x4000 0x2 0x8cdd0000 0x0 0x4000 0x2 0x8cdd8000 0x0 0x4000 0x2 0x8cde0000 0x0 0x4000>;
		interrupts = <0x0 0x0 0x388 0x4 0x0 0x0 0x389 0x4 0x0 0x0 0x38a 0x4 0x0 0x0 0x38b 0x4 0x0 0x0 0x38c 0x4 0x0 0x0 0x38d 0x4 0x0 0x0 0x38e 0x4 0x0 0x0 0x38f 0x4 0x0 0x0 0x390 0x4 0x0 0x0 0x391 0x4 0x0 0x0 0x392 0x4 0x0 0x0 0x393 0x4 0x0 0x0 0x394 0x4 0x0 0x0 0x395 0x4 0x0 0x0 0x396 0x4 0x0 0x0 0x397 0x4 0x0 0x0 0x398 0x4 0x0 0x0 0x399 0x4 0x0 0x0 0x39a 0x4 0x0 0x0 0x39b 0x4 0x0 0x0 0x39c 0x4 0x0 0x0 0x39d 0x4 0x0 0x0 0x39e 0x4 0x0 0x0 0x39f 0x4 0x0 0x0 0x3a0 0x4 0x0 0x0 0x3a1 0x4 0x0 0x0 0x3a2 0x4 0x0 0x0 0x3a3 0x4 0x0 0x0 0x3a4 0x4 0x0 0x0 0x3a5 0x4 0x0 0x0 0x3a6 0x4 0x0 0x0 0x3a7 0x4>;
		interrupt-controller;
		#interrupt-cells = <0x1>;
		#address-cells = <0x0>;
		status = "disabled";
	};
};

&{/soc} {
	rsm@288825000 {
		compatible = "apple,t6050-rsm", "apple,rsm";
		reg = <0x2 0x88825000 0x0 0x4000 0x2 0x888c0000 0x0 0x4>;
		interrupts = <0x0 0x0 0x1ef 0x4>;
		iommus = <&{/soc/iommu@2889a0000} 0x0>;
		power-domains = <&{/soc/power-management@288300000/power-controller@58}>;
		status = "disabled";
	};
};

&{/soc} {
	iommu@2889a0000 {
		compatible = "apple,t6050-dart", "apple,t8110-dart";
		reg = <0x2 0x889a0000 0x0 0xc000>;
		interrupts = <0x0 0x0 0x1f2 0x4>;
		#iommu-cells = <0x1>;
		status = "disabled";
	};
};

&{/soc} {
	serial@505200000 {
		compatible = "apple,t6050-uart", "apple,s5l-uart";
		reg = <0x5 0x5200000 0x0 0x4000>;
		interrupts = <0x0 0x0 0x54f 0x4>;
		power-domains = <&{/soc/power-management@280900000/power-controller@360}>;
		clocks = <&{/soc/clock-controller@280600000} 0x1c9 &{/soc/clock-controller@280600000} 0x4>;
		clock-names = "uart", "clk_uart_baud0";
		status = "disabled";
	};
};

&{/soc} {
	spmi@28a094000 {
		compatible = "apple,t6050-spmi", "apple,t8142-spmi";
		reg = <0x2 0x8a094000 0x0 0x4000 0x2 0x8a084000 0x0 0x4000 0x2 0x8a080000 0x0 0x4000>;
		interrupts = <0x0 0x0 0x2e0 0x4>;
		#address-cells = <0x2>;
		#size-cells = <0x0>;
		status = "disabled";
	};
};

&{/soc} {
	spmi@28a0d4000 {
		compatible = "apple,t6050-spmi", "apple,t8142-spmi";
		reg = <0x2 0x8a0d4000 0x0 0x4000 0x2 0x8a0c4000 0x0 0x4000 0x2 0x8a0c0000 0x0 0x4000>;
		interrupts = <0x0 0x0 0x2e5 0x4>;
		#address-cells = <0x2>;
		#size-cells = <0x0>;
		status = "disabled";
	};
};

&{/soc} {
	spmi@290914000 {
		compatible = "apple,t6050-spmi", "apple,t8142-spmi";
		reg = <0x2 0x90914000 0x0 0x4000 0x2 0x90904000 0x0 0x4000 0x2 0x90900000 0x0 0x4000>;
		interrupts = <0x0 0x0 0x26c 0x4>;
		#address-cells = <0x2>;
		#size-cells = <0x0>;
		status = "disabled";
	};
};

&{/soc} {
	scaler@2285000000 {
		compatible = "apple,t6050-scaler", "apple,scaler-v23";
		reg = <0x22 0x85000000 0x0 0x14000 0x22 0x85210000 0x0 0x4000 0x22 0x85204000 0x0 0x4000 0x22 0x84000000 0x0 0x8000 0x22 0x852c0000 0x0 0x40000 0x22 0x85340000 0x0 0x14c000 0x22 0x852a0000 0x0 0x4000 0x22 0x85208000 0x0 0x4000 0x22 0x85210000 0x0 0x4000 0x22 0x85220000 0x0 0x4000>;
		interrupts = <0x0 0x0 0x9a4 0x4 0x0 0x0 0x9a6 0x4 0x0 0x0 0x9a7 0x4 0x0 0x0 0x9a8 0x4 0x0 0x0 0x9ac 0x4 0x0 0x0 0x9ad 0x4 0x0 0x0 0x9ae 0x4 0x0 0x0 0x9af 0x4 0x0 0x0 0x9b0 0x4 0x0 0x0 0x9b1 0x4 0x0 0x0 0x9b2 0x4 0x0 0x0 0x9b3 0x4 0x0 0x0 0x9b4 0x4 0x0 0x0 0x9b5 0x4 0x0 0x0 0x9b6 0x4 0x0 0x0 0x9b7 0x4 0x0 0x0 0x9b8 0x4 0x0 0x0 0x9b9 0x4 0x0 0x0 0x9ba 0x4 0x0 0x0 0x9bb 0x4>;
		iommus = <&{/soc/iommu@2285260000} 0x0 &{/soc/iommu@2285260000} 0x1>;
		power-domains = <&{/soc/power-management@2380600000/power-controller@1c8} &{/soc/power-management@2380600000/power-controller@200}>;
		clocks = <&{/soc/clock-controller@280600000} 0x1f0>;
		resets = <&{/soc/power-management@2380600000/power-controller@1c8}>;
		status = "disabled";
	};
};

&{/soc} {
	iommu@2285260000 {
		compatible = "apple,t6050-dart", "apple,t8110-dart";
		reg = <0x22 0x85260000 0x0 0x20000 0x2 0x74000000 0x0 0x4000>;
		interrupts = <0x0 0x0 0x9a5 0x4>;
		power-domains = <&{/soc/power-management@2380600000/power-controller@1c8}>;
		#iommu-cells = <0x1>;
		status = "disabled";
	};
};

&{/soc} {
	scaler@23a1000000 {
		compatible = "apple,t6050-scaler", "apple,scaler-v23";
		reg = <0x23 0xa1000000 0x0 0x14000 0x23 0xa1210000 0x0 0x4000 0x23 0xa1204000 0x0 0x4000 0x23 0xa0000000 0x0 0x8000 0x23 0xa12c0000 0x0 0x40000 0x23 0xa1340000 0x0 0x14c000 0x23 0xa12a0000 0x0 0x4000 0x23 0xa1208000 0x0 0x4000 0x23 0xa1210000 0x0 0x4000 0x23 0xa1220000 0x0 0x4000>;
		interrupts = <0x0 0x0 0x9bc 0x4 0x0 0x0 0x9be 0x4 0x0 0x0 0x9bf 0x4 0x0 0x0 0x9c0 0x4 0x0 0x0 0x9c4 0x4 0x0 0x0 0x9c5 0x4 0x0 0x0 0x9c6 0x4 0x0 0x0 0x9c7 0x4 0x0 0x0 0x9c8 0x4 0x0 0x0 0x9c9 0x4 0x0 0x0 0x9ca 0x4 0x0 0x0 0x9cb 0x4 0x0 0x0 0x9cc 0x4 0x0 0x0 0x9cd 0x4 0x0 0x0 0x9ce 0x4 0x0 0x0 0x9cf 0x4 0x0 0x0 0x9d0 0x4 0x0 0x0 0x9d1 0x4 0x0 0x0 0x9d2 0x4 0x0 0x0 0x9d3 0x4>;
		iommus = <&{/soc/iommu@23a1260000} 0x0 &{/soc/iommu@23a1260000} 0x1>;
		power-domains = <&{/soc/power-management@2380600000/power-controller@1f8} &{/soc/power-management@2380600000/power-controller@208}>;
		clocks = <&{/soc/clock-controller@280600000} 0x1f1>;
		resets = <&{/soc/power-management@2380600000/power-controller@1f8}>;
		status = "disabled";
	};
};

&{/soc} {
	iommu@23a1260000 {
		compatible = "apple,t6050-dart", "apple,t8110-dart";
		reg = <0x23 0xa1260000 0x0 0x20000 0x2 0x74000000 0x0 0x4000>;
		interrupts = <0x0 0x0 0x9bd 0x4>;
		power-domains = <&{/soc/power-management@2380600000/power-controller@1f8}>;
		#iommu-cells = <0x1>;
		status = "disabled";
	};
};

&{/soc} {
	video-encoder@2283100000 {
		compatible = "apple,t6050-ave", "apple,ave";
		reg = <0x22 0x83100000 0x0 0x45c000 0x22 0x83800000 0x0 0x800000 0x22 0x83050000 0x0 0x4000 0x23 0x806001c0 0x0 0x7e64 0x22 0x82000000 0x0 0x8000>;
		interrupts = <0x0 0x0 0x983 0x4 0x0 0x0 0xae6 0x4 0x0 0x0 0xae5 0x4 0x0 0x0 0xae8 0x4 0x0 0x0 0xae7 0x4>;
		iommus = <&{/soc/iommu@22830a0000} 0x0 &{/soc/iommu@2283080000} 0x0>;
		power-domains = <&{/soc/power-management@2380600000/power-controller@1c0} &{/soc/power-management@2380600000/power-controller@8008} &{/soc/power-management@2380600000/power-controller@8010} &{/soc/power-management@2380600000/power-controller@8018} &{/soc/power-management@2380600000/power-controller@8020} &{/soc/power-management@2380600000/power-controller@8000}>;
		clocks = <&{/soc/clock-controller@280600000} 0x1f7>;
		status = "disabled";
	};
};

&{/soc} {
	iommu@22830a0000 {
		compatible = "apple,t6050-dart", "apple,t8110-dart";
		reg = <0x22 0x830a0000 0x0 0xc000 0x22 0x830b0000 0x0 0x4000>;
		interrupts = <0x0 0x0 0x980 0x4>;
		power-domains = <&{/soc/power-management@2380600000/power-controller@1c0}>;
		#iommu-cells = <0x1>;
		status = "disabled";
	};
};

&{/soc} {
	iommu@2283080000 {
		compatible = "apple,t6050-dart", "apple,t8110-dart";
		reg = <0x22 0x83080000 0x0 0xc000 0x22 0x83094000 0x0 0x4000>;
		interrupts = <0x0 0x0 0x980 0x4>;
		power-domains = <&{/soc/power-management@2380600000/power-controller@1c0}>;
		#iommu-cells = <0x1>;
		status = "disabled";
	};
};

&{/soc} {
	video-encoder@23a3100000 {
		compatible = "apple,t6050-ave", "apple,ave";
		reg = <0x23 0xa3100000 0x0 0x45c000 0x23 0xa3800000 0x0 0x800000 0x23 0xa3050000 0x0 0x4000 0x23 0x806001f0 0x0 0x7e5c 0x23 0xa2000000 0x0 0x8000>;
		interrupts = <0x0 0x0 0x98b 0x4 0x0 0x0 0xaea 0x4 0x0 0x0 0xae9 0x4 0x0 0x0 0xaec 0x4 0x0 0x0 0xaeb 0x4>;
		iommus = <&{/soc/iommu@23a30a0000} 0x0 &{/soc/iommu@23a3080000} 0x0>;
		power-domains = <&{/soc/power-management@2380600000/power-controller@1f0} &{/soc/power-management@2380600000/power-controller@8030} &{/soc/power-management@2380600000/power-controller@8038} &{/soc/power-management@2380600000/power-controller@8040} &{/soc/power-management@2380600000/power-controller@8048} &{/soc/power-management@2380600000/power-controller@8028}>;
		clocks = <&{/soc/clock-controller@280600000} 0x1f8>;
		status = "disabled";
	};
};

&{/soc} {
	iommu@23a30a0000 {
		compatible = "apple,t6050-dart", "apple,t8110-dart";
		reg = <0x23 0xa30a0000 0x0 0xc000 0x23 0xa30b0000 0x0 0x4000>;
		interrupts = <0x0 0x0 0x988 0x4>;
		power-domains = <&{/soc/power-management@2380600000/power-controller@1f0}>;
		#iommu-cells = <0x1>;
		status = "disabled";
	};
};

&{/soc} {
	iommu@23a3080000 {
		compatible = "apple,t6050-dart", "apple,t8110-dart";
		reg = <0x23 0xa3080000 0x0 0xc000 0x23 0xa3094000 0x0 0x4000>;
		interrupts = <0x0 0x0 0x988 0x4>;
		power-domains = <&{/soc/power-management@2380600000/power-controller@1f0}>;
		#iommu-cells = <0x1>;
		status = "disabled";
	};
};

&{/soc} {
	prores@48d000000 {
		compatible = "apple,t6050-prores", "apple,prores";
		reg = <0x4 0x8d000000 0x0 0x4000 0x4 0x8c000000 0x0 0x1000000 0x4 0x8d0c0000 0x0 0x4000 0x4 0x8d070000 0x0 0x4000 0x4 0x8d071000 0x0 0x4000>;
		interrupts = <0x0 0x0 0x6b1 0x4 0x0 0x0 0x6d6 0x4>;
		iommus = <&{/soc/iommu@48d020000} 0x1>;
		power-domains = <&{/soc/power-management@280900000/power-controller@190}>;
		status = "disabled";
	};
};

&{/soc} {
	iommu@48d020000 {
		compatible = "apple,t6050-dart", "apple,t8110-dart";
		reg = <0x4 0x8d020000 0x0 0xc000>;
		interrupts = <0x0 0x0 0x6b0 0x4>;
		power-domains = <&{/soc/power-management@280900000/power-controller@190}>;
		#iommu-cells = <0x1>;
		status = "disabled";
	};
};

&{/soc} {
	iommu@230b020000 {
		compatible = "apple,t6050-dart", "apple,t8110-dart";
		reg = <0x23 0xb020000 0x0 0xc000 0x2 0x74000000 0x0 0x4000>;
		interrupts = <0x0 0x0 0x6e0 0x4>;
		power-domains = <&{/soc/power-management@2380600000/power-controller@1e0}>;
		#iommu-cells = <0x1>;
		status = "disabled";
	};
};

&{/soc} {
	jpeg@2281000000 {
		compatible = "apple,t6050-jpeg", "apple,jpeg";
		reg = <0x22 0x81000000 0x0 0x20000>;
		interrupts = <0x0 0x0 0x54b 0x4>;
		iommus = <&{/soc/iommu@2281020000} 0x0>;
		power-domains = <&{/soc/power-management@2380600000/power-controller@1d0}>;
		clocks = <&{/soc/clock-controller@280600000} 0x1e6 &{/soc/clock-controller@280600000} 0x1e7>;
		status = "disabled";
	};
};

&{/soc} {
	jpeg@2281060000 {
		compatible = "apple,t6050-jpeg", "apple,jpeg";
		reg = <0x22 0x81060000 0x0 0x44000>;
		interrupts = <0x0 0x0 0x54e 0x4>;
		iommus = <&{/soc/iommu@2281020000} 0x1>;
		power-domains = <&{/soc/power-management@2380600000/power-controller@1d0}>;
		clocks = <&{/soc/clock-controller@280600000} 0x1e6 &{/soc/clock-controller@280600000} 0x1e7>;
		status = "disabled";
	};
};

&{/soc} {
	iommu@2281020000 {
		compatible = "apple,t6050-dart", "apple,t8110-dart";
		reg = <0x22 0x81020000 0x0 0xc000 0x2 0x74000000 0x0 0x4000>;
		interrupts = <0x0 0x0 0x54c 0x4>;
		power-domains = <&{/soc/power-management@2380600000/power-controller@1d0}>;
		#iommu-cells = <0x1>;
		status = "disabled";
	};
};

&{/soc} {
	neural-processor@508000000 {
		compatible = "apple,t6050-ane";
		reg = <0x5 0x8000000 0x0 0x2000000 0x2 0x80900000 0x0 0x18000 0x2 0x80920000 0x0 0x4000 0x2 0x84240000 0x0 0x40000 0x2 0x12000000 0x0 0xff4000 0x5 0x84000000 0x0 0x2000000 0x2 0x88374000 0x0 0x4000>;
		reg-names = "engine", "pmgr", "aux-0", "aux-1", "aux-2", "aux-3", "aux-4";
		interrupts = <0x0 0x0 0x3ba 0x4 0x0 0x0 0x3c7 0x4>;
		iommus = <&{/soc/iommu@509800000} 0x0 &{/soc/iommu@509820000} 0x0 &{/soc/iommu@509840000} 0x0>;
		power-domains = <&{/soc/power-management@280900000/power-controller@3c8}>;
		clocks = <&{/soc/clock-controller@280600000} 0x14f &{/soc/clock-controller@280600000} 0x14e &{/soc/clock-controller@280600000} 0x17d>;
		status = "disabled";
	};
};

&{/soc} {
	video-decoder@2308000000 {
		compatible = "apple,t6050-avd", "apple,avd";
		reg = <0x23 0x8000000 0x0 0x1404000 0x23 0x88090000 0x0 0x4000>;
		interrupts = <0x0 0x0 0x971 0x4 0x0 0x0 0x972 0x4>;
		iommus = <&{/soc/iommu@2309020000} 0x0 &{/soc/iommu@2309020000} 0x1 &{/soc/iommu@2309020000} 0x2>;
		power-domains = <&{/soc/power-management@2380600000/power-controller@1d8}>;
		clocks = <&{/soc/clock-controller@280600000} 0x1e8>;
		status = "disabled";
	};
};

&{/soc} {
	dma-controller@293300000 {
		compatible = "apple,t6050-admac", "apple,t8140-admac";
		reg = <0x2 0x93300000 0x0 0x34000>;
		dma-channels = <0x9>;
		interrupts-extended = <&{/soc/interrupt-controller@280400000} 0x0 0x0 0x27f 0x4 0 0 0>;
		iommus = <&{/soc/iommu@290fc0000} 0xa>;
		#dma-cells = <0x1>;
		status = "disabled";
	};
};

&{/soc} {
	dma-control@293c80000 {
		compatible = "apple,t6050-admac-control", "apple,admac-control";
		reg = <0x2 0x93c80000 0x0 0x4000 0x2 0x93c84000 0x0 0x4000>;
		interrupts = <0x0 0x0 0x28c 0x4>;
		status = "disabled";
	};
};

&{/soc} {
	message-controller@29b000000 {
		compatible = "apple,t6050-msg", "apple,msg";
		reg = <0x2 0x9b000000 0x0 0xb4000 0x2 0x99000000 0x0 0x4000>;
		interrupts = <0x0 0x0 0x319 0x4 0x0 0x0 0x31a 0x4 0x0 0x0 0x31b 0x4 0x0 0x0 0x31c 0x4 0x0 0x0 0x31d 0x4 0x0 0x0 0x31e 0x4 0x0 0x0 0x31f 0x4 0x0 0x0 0x320 0x4 0x0 0x0 0x321 0x4 0x0 0x0 0x322 0x4 0x0 0x0 0x323 0x4 0x0 0x0 0x324 0x4 0x0 0x0 0x325 0x4 0x0 0x0 0x326 0x4 0x0 0x0 0x327 0x4 0x0 0x0 0x328 0x4 0x0 0x0 0x329 0x4 0x0 0x0 0x32a 0x4 0x0 0x0 0x32b 0x4 0x0 0x0 0x32c 0x4 0x0 0x0 0x32d 0x4 0x0 0x0 0x32e 0x4 0x0 0x0 0x32f 0x4 0x0 0x0 0x330 0x4 0x0 0x0 0x331 0x4 0x0 0x0 0x332 0x4 0x0 0x0 0x333 0x4 0x0 0x0 0x334 0x4 0x0 0x0 0x335 0x4 0x0 0x0 0x336 0x4 0x0 0x0 0x337 0x4 0x0 0x0 0x338 0x4 0x0 0x0 0x339 0x4 0x0 0x0 0x33a 0x4 0x0 0x0 0x33b 0x4 0x0 0x0 0x33c 0x4 0x0 0x0 0x33d 0x4 0x0 0x0 0x33e 0x4 0x0 0x0 0x33f 0x4 0x0 0x0 0x340 0x4 0x0 0x0 0x318 0x4>;
		power-domains = <&{/soc/power-management@280600000/power-controller@258}>;
		status = "disabled";
	};
};

&{/soc} {
	dma-controller@412030000 {
		compatible = "apple,t6050-pcie-piodma", "apple,pcie-piodma";
		reg = <0x4 0x12030000 0x0 0x4000 0x4 0x12034000 0x0 0x4000 0x4 0x12038000 0x0 0x4000>;
		interrupts = <0x0 0x0 0x605 0x4>;
		iommus = <&{/soc/iommu@412000000} 0x11>;
		status = "disabled";
	};
};

&{/soc} {
	dma-controller@413030000 {
		compatible = "apple,t6050-pcie-piodma", "apple,pcie-piodma";
		reg = <0x4 0x13030000 0x0 0x4000 0x4 0x13034000 0x0 0x4000 0x4 0x13038000 0x0 0x4000>;
		interrupts = <0x0 0x0 0x60d 0x4>;
		iommus = <&{/soc/iommu@413000000} 0x11>;
		status = "disabled";
	};
};

&{/soc} {
	spi@50510c000 {
		compatible = "apple,t6050-spi", "apple,t8103-spi";
		reg = <0x5 0x510c000 0x0 0x4000>;
		interrupts = <0x0 0x0 0x55a 0x4>;
		power-domains = <&{/soc/power-management@280900000/power-controller@338}>;
		clocks = <&{/soc/clock-controller@280600000} 0x1c4>;
		#address-cells = <0x1>;
		#size-cells = <0x0>;
		status = "disabled";
	};
};

&{/soc} {
	dma-controller@38c068000 {
		compatible = "apple,t6050-pciec-piodma", "apple,pciec-piodma";
		reg = <0x3 0x8c068000 0x0 0x4000 0x3 0x8c06c000 0x0 0x4000 0x3 0x8c070000 0x0 0x4000 0x3 0x8c03c000 0x0 0x4000>;
		interrupts = <0x0 0x0 0x5df 0x4>;
		iommus = <&{/soc/iommu@38c000000} 0xfe>;
		status = "disabled";
	};
};

&{/soc} {
	dpin@389e50000 {
		compatible = "apple,t6050-dpin", "apple,dpin";
		reg = <0x3 0x89e50000 0x0 0x4000>;
		interrupts = <0x0 0x0 0x6a3 0x4>;
		status = "disabled";
	};
};

&{/soc} {
	dpin@389e58000 {
		compatible = "apple,t6050-dpin", "apple,dpin";
		reg = <0x3 0x89e58000 0x0 0x4000>;
		interrupts = <0x0 0x0 0x6a4 0x4>;
		status = "disabled";
	};
};

&{/soc} {
	dpin@389e68000 {
		compatible = "apple,t6050-dpin", "apple,dpin";
		reg = <0x3 0x89e68000 0x0 0x4000>;
		interrupts = <0x0 0x0 0x6a9 0x4>;
		status = "disabled";
	};
};

&{/soc} {
	dpin@389e70000 {
		compatible = "apple,t6050-dpin", "apple,dpin";
		reg = <0x3 0x89e70000 0x0 0x4000>;
		interrupts = <0x0 0x0 0x6aa 0x4>;
		status = "disabled";
	};
};
